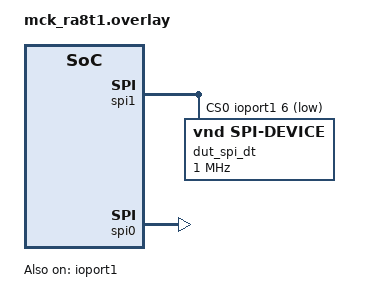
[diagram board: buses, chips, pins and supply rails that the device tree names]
/*
 * Copyright (c) 2025 Renesas Electronics Corporation
 * SPDX-License-Identifier: Apache-2.0
 */

&pinctrl {
	spi1_default: spi1_default {
		group1 {
			/* MISO MOSI RSPCK */
			psels = <RA_PSEL(RA_PSEL_SPI, 1, 0)>,
				<RA_PSEL(RA_PSEL_SPI, 1, 1)>,
				<RA_PSEL(RA_PSEL_SPI, 1, 2)>;
		};
	};
};

&ioport1 {
	status = "okay";
};

&spi1 {
	rx-dtc;
	tx-dtc;
	status = "okay";
	pinctrl-0 = <&spi1_default>;
	pinctrl-names = "default";
	cs-gpios = <&ioport1 6 GPIO_ACTIVE_LOW>;

	dut_spi_dt: test-spi-dev@0 {
		compatible = "vnd,spi-device";
		reg = <0>;
		spi-max-frequency = <1000000>;
	};
};

dut_spis: &spi0 {
	rx-dtc;
	tx-dtc;
	status = "okay";
};
